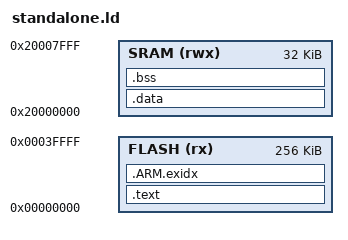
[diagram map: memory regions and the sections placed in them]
/******************************************************************************
 *
 * standalone.ld - Linker script for applications using startup.c and
 *                 DriverLib.
 *
 * Copyright (c) 2005-2007 Luminary Micro, Inc.  All rights reserved.
 *
 * Software License Agreement
 *
 * Luminary Micro, Inc. (LMI) is supplying this software for use solely and
 * exclusively on LMI's microcontroller products.
 *
 * The software is owned by LMI and/or its suppliers, and is protected under
 * applicable copyright laws.  All rights are reserved.  Any use in violation
 * of the foregoing restrictions may subject the user to criminal sanctions
 * under applicable laws, as well as to civil liability for the breach of the
 * terms and conditions of this license.
 *
 * THIS SOFTWARE IS PROVIDED "AS IS".  NO WARRANTIES, WHETHER EXPRESS, IMPLIED
 * OR STATUTORY, INCLUDING, BUT NOT LIMITED TO, IMPLIED WARRANTIES OF
 * MERCHANTABILITY AND FITNESS FOR A PARTICULAR PURPOSE APPLY TO THIS SOFTWARE.
 * LMI SHALL NOT, IN ANY CIRCUMSTANCES, BE LIABLE FOR SPECIAL, INCIDENTAL, OR
 * CONSEQUENTIAL DAMAGES, FOR ANY REASON WHATSOEVER.
 *
 * This is part of revision 1049 of the Stellaris Driver Library.
 *
 *****************************************************************************/

ENTRY(Reset_Handler)

MEMORY
{
    FLASH (rx) : ORIGIN = 0x00000000, LENGTH = 256K
    SRAM (rwx) : ORIGIN = 0x20000000, LENGTH = 32K
}

SECTIONS
{
    .text :
    {
        _text = .;
	KEEP(*(.isr_vector))
        *(.text*)
        *(.rodata*)
		_etext = .;
    } > FLASH
	
	_exidx_start = .;
	.ARM.exidx :
	{
		*(.ARM.exidx* .gnu.linkonce.armexidx.*)
	} > FLASH
	__exidx_end = .;

    .data : AT (__exidx_end)
    {
        _data = .;
        _ldata = LOADADDR (.data);
		*(vtable)
        *(.data*)
        _edata = .;
    } > SRAM

    .bss :
    {
        _bss = .;
        *(.bss*)
        *(COMMON)
        _ebss = .;
    } > SRAM

	. = ALIGN(4);
	_heap_start = .;
	_heap_limit = ORIGIN(SRAM) + LENGTH(SRAM);
}
